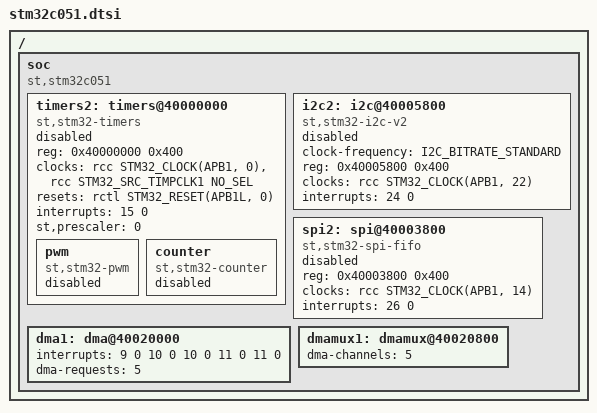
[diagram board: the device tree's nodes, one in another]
/*
 * Copyright (c) 2024 STMicroelectronics
 * Copyright (c) 2025 Thomas Stranger
 *
 * SPDX-License-Identifier: Apache-2.0
 */

#include <st/c0/stm32c031.dtsi>

/ {
	soc {
		compatible = "st,stm32c051", "st,stm32c0", "simple-bus";

		timers2: timers@40000000 {
			compatible = "st,stm32-timers";
			reg = <0x40000000 0x400>;
			clocks = <&rcc STM32_CLOCK(APB1, 0)>,
				 <&rcc STM32_SRC_TIMPCLK1 NO_SEL>;
			resets = <&rctl STM32_RESET(APB1L, 0)>;
			interrupts = <15 0>;
			interrupt-names = "global";
			st,prescaler = <0>;
			status = "disabled";

			pwm {
				compatible = "st,stm32-pwm";
				status = "disabled";
				#pwm-cells = <3>;
			};

			counter {
				compatible = "st,stm32-counter";
				status = "disabled";
			};
		};

		i2c2: i2c@40005800 {
			compatible = "st,stm32-i2c-v2";
			clock-frequency = <I2C_BITRATE_STANDARD>;
			#address-cells = <1>;
			#size-cells = <0>;
			reg = <0x40005800 0x400>;
			clocks = <&rcc STM32_CLOCK(APB1, 22)>;
			interrupts = <24 0>;
			interrupt-names = "global";
			status = "disabled";
		};

		spi2: spi@40003800 {
			compatible = "st,stm32-spi-fifo", "st,stm32-spi";
			#address-cells = <1>;
			#size-cells = <0>;
			reg = <0x40003800 0x400>;
			clocks = <&rcc STM32_CLOCK(APB1, 14)>;
			interrupts = <26 0>;
			interrupt-names = "global";
			status = "disabled";
		};

		dma1: dma@40020000 {
			interrupts = <9 0 10 0 10 0 11 0 11 0>;
			dma-requests = <5>;
		};

		dmamux1: dmamux@40020800 {
			dma-channels = <5>;
		};
	};
};
